# K32L2B21A register map
Vendor: NXP Semiconductors; Series: Kinetis; File version: 1.6
CPU: CM0PLUS r0p0, little endian, no MPU, no FPU, VTOR, 2 interrupt priority bits
Registers are 32-bit, read-write, reset 0x0 unless marked. A register's access mark holds for its fields unless they carry their own. Offsets are from the block's base; [hi:lo] are bit positions; {n}, {i} and the like mark numbered series; 'fields as' and 'values as' point back to an identical list.

## PORTB — Pin Control and Interrupts
Base 0x4004A000; register names take the prefix PORTB_
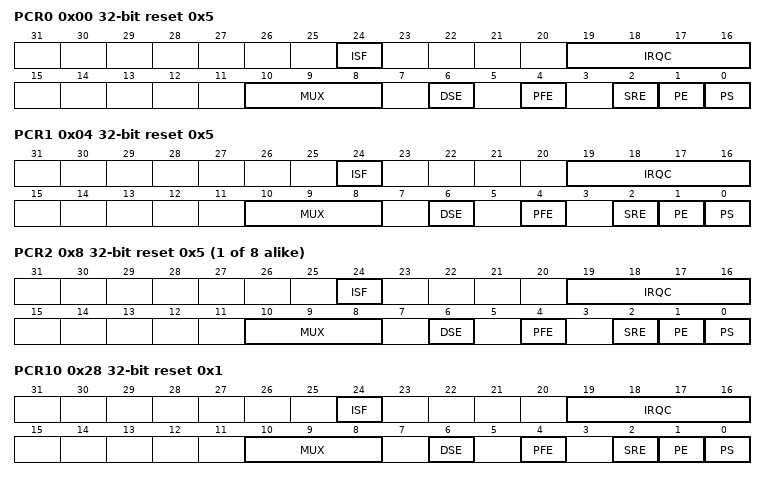
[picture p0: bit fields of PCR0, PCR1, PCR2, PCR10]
0x00 PCR0 reset 0x5 — Pin Control Register n
  [24] ISF — Interrupt Status Flag
    0=Configured interrupt is not detected; 1=Configured interrupt is detected. If the pin is configured to generate a DMA request, then the corresponding flag will be cleared automatically at the completion of the requested DMA transfer. Otherwise, the flag remains set until a logic 1 is written to the flag. If the pin is configured for a level sensitive interrupt and the pin remains asserted, then the flag is set again immediately after it is cleared.
  [19:16] IRQC — Interrupt Configuration
    0=Interrupt Status Flag (ISF) is disabled; 1=ISF flag and DMA request on rising edge; 2=ISF flag and DMA request on falling edge; 3=ISF flag and DMA request on either edge; 8=ISF flag and Interrupt when logic 0; 9=ISF flag and Interrupt on rising-edge; 10=ISF flag and Interrupt on falling-edge; 11=ISF flag and Interrupt on either edge; 12=ISF flag and Interrupt when logic 1
  [10:8] MUX — Pin Mux Control
    0=Pin disabled (Alternative 0) (analog); 1=Alternative 1 (GPIO); {v}=Alternative {v} (chip-specific) (v=2..7)
  [6] DSE — Drive Strength Enable
    0=Low drive strength is configured on the corresponding pin, if pin is configured as a digital output; 1=High drive strength is configured on the corresponding pin, if pin is configured as a digital output
  [4] PFE ro — Passive Filter Enable
    0=Passive input filter is disabled on the corresponding pin; 1=Passive input filter is enabled on the corresponding pin, if the pin is configured as a digital input. Refer to the device data sheet for filter characteristics.
  [2] SRE — Slew Rate Enable
    0=Fast slew rate is configured on the corresponding pin, if the pin is configured as a digital output; 1=Slow slew rate is configured on the corresponding pin, if the pin is configured as a digital output
  [1] PE — Pull Enable
    0=Internal pullup or pulldown resistor is not enabled on the corresponding pin; 1=Internal pullup or pulldown resistor is enabled on the corresponding pin, if the pin is configured as a digital input
  [0] PS — Pull Select
    0=Internal pulldown resistor is enabled on the corresponding pin, if the corresponding PE field is set; 1=Internal pullup resistor is enabled on the corresponding pin, if the corresponding PE field is set
0x04 PCR1 reset 0x5 — Pin Control Register n
  fields as PCR0
{0x0+4i} PCR{i} reset 0x5 (i=2..9) — Pin Control Register n
  [24] ISF — Interrupt Status Flag
    values as PCR0.ISF
  [19:16] IRQC — Interrupt Configuration
    values as PCR0.IRQC
  [10:8] MUX — Pin Mux Control
    values as PCR0.MUX
  [6] DSE ro — Drive Strength Enable
    values as PCR0.DSE
  [4] PFE ro — Passive Filter Enable
    values as PCR0.PFE
  [2] SRE ro — Slew Rate Enable
    values as PCR0.SRE
  [1] PE ro — Pull Enable
    values as PCR0.PE
  [0] PS ro — Pull Select
    values as PCR0.PS
0x28 PCR10 reset 0x1 — Pin Control Register n
  fields as PCR2
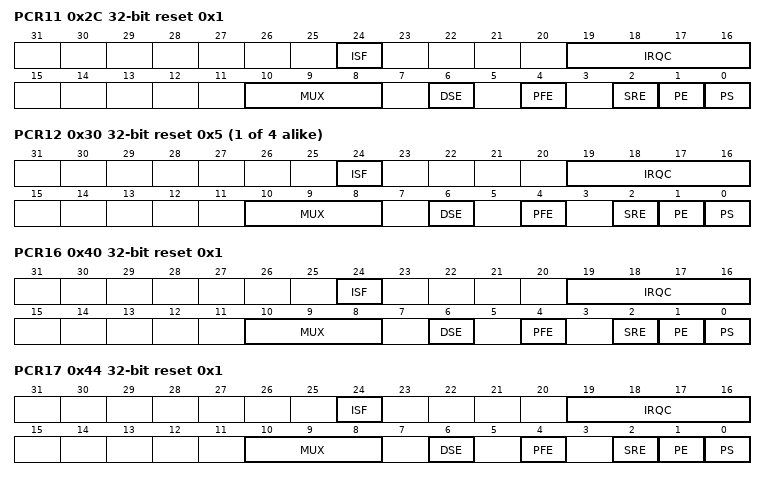
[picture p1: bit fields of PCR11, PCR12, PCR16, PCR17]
0x2C PCR11 reset 0x1 — Pin Control Register n
  fields as PCR2
{0x0+4i} PCR{i} reset 0x5 (i=12..15) — Pin Control Register n
  fields as PCR2
0x40 PCR16 reset 0x1 — Pin Control Register n
  fields as PCR2
0x44 PCR17 reset 0x1 — Pin Control Register n
  fields as PCR2
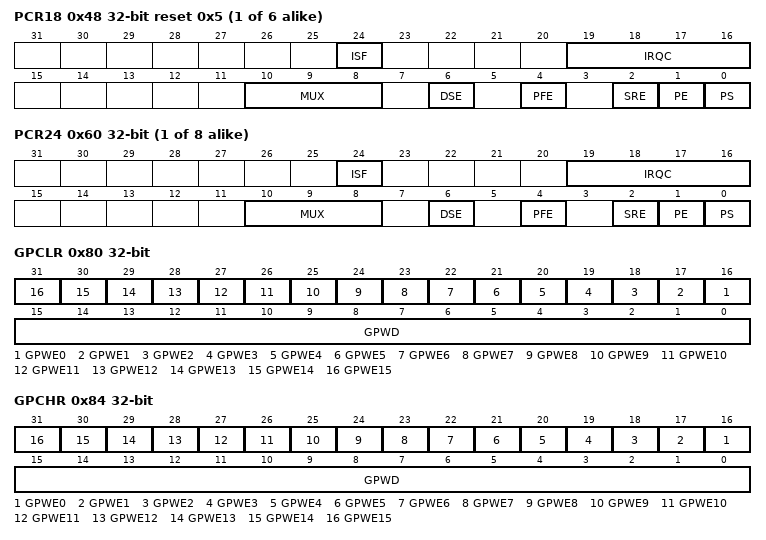
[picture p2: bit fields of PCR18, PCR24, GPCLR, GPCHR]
{0x0+4i} PCR{i} reset 0x5 (i=18..23) — Pin Control Register n
  fields as PCR2
{0x0+4i} PCR{i} (i=24..31) — Pin Control Register n
  fields as PCR2
0x80 GPCLR — Global Pin Control Low Register
  [n+16] GPWE{n} (n=0..15) — Global Pin Write Enable
    0=Corresponding Pin Control Register is not updated with the value in GPWD; 1=Corresponding Pin Control Register is updated with the value in GPWD
  [15:0] GPWD — Global Pin Write Data
0x84 GPCHR — Global Pin Control High Register
  fields as GPCLR
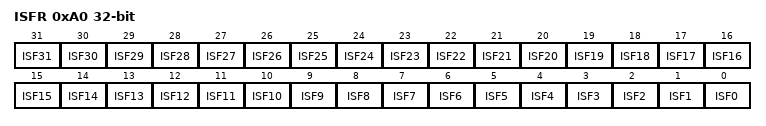
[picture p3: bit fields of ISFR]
0xA0 ISFR — Interrupt Status Flag Register
  [all] fields
    values as PCR0.ISF
  [n] ISF{n} (n=0..31) — Interrupt Status Flag

## PORTC — Pin Control and Interrupts
Base 0x4004B000; register names take the prefix PORTC_
Registers as PORTB; these are added or differ:
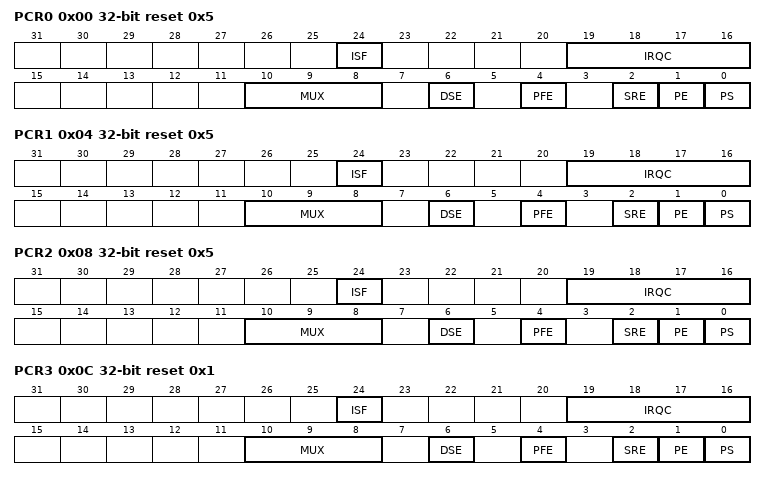
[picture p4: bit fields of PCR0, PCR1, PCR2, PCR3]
0x00 PCR0 reset 0x5 — Pin Control Register n
  fields as PORTB.PCR2
0x04 PCR1 reset 0x5 — Pin Control Register n
  [24] ISF — Interrupt Status Flag
    values as PORTB.PCR0.ISF
  [19:16] IRQC — Interrupt Configuration
    values as PORTB.PCR0.IRQC
  [10:8] MUX — Pin Mux Control
    0=Pin disabled (Alternative 0) (analog); 1=Alternative 1 (GPIO); {v}=Alternative {v} (chip-specific) (v=2..7)
  [6] DSE ro — Drive Strength Enable
    values as PORTB.PCR0.DSE
  [4] PFE ro — Passive Filter Enable
    values as PORTB.PCR0.PFE
  [2] SRE — Slew Rate Enable
    values as PORTB.PCR0.SRE
  [1] PE — Pull Enable
    0=Internal pullup or pulldown resistor is not enabled on the corresponding pin; 1=Internal pullup or pulldown resistor is enabled on the corresponding pin, if the pin is configured as a digital input
  [0] PS — Pull Select
    values as PORTB.PCR0.PS
0x08 PCR2 reset 0x5 — Pin Control Register n
  fields as PCR1
0x0C PCR3 reset 0x1 — Pin Control Register n
  fields as PORTB.PCR0
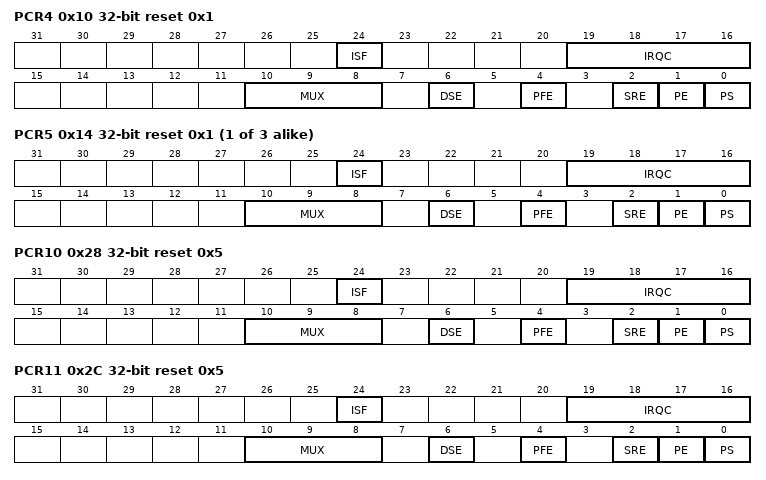
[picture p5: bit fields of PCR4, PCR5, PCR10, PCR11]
0x10 PCR4 reset 0x1 — Pin Control Register n
  fields as PORTB.PCR0
{0x0+4i} PCR{i} reset 0x1 (i=5..7) — Pin Control Register n
  fields as PCR1
0x28 PCR10 reset 0x5 — Pin Control Register n
  fields as PORTB.PCR2
0x2C PCR11 reset 0x5 — Pin Control Register n
  fields as PORTB.PCR2
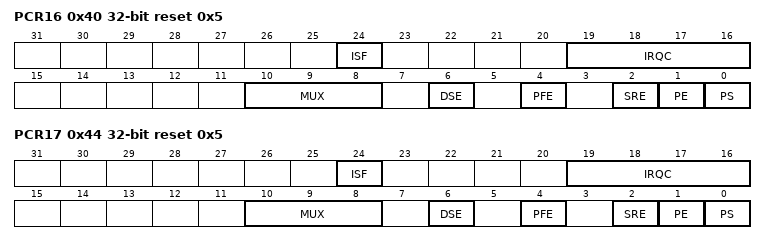
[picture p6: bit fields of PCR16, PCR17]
0x40 PCR16 reset 0x5 — Pin Control Register n
  fields as PORTB.PCR2
0x44 PCR17 reset 0x5 — Pin Control Register n
  fields as PORTB.PCR2

## PORTD — Pin Control and Interrupts
Base 0x4004C000; register names take the prefix PORTD_
Registers as PORTC; these are added or differ:
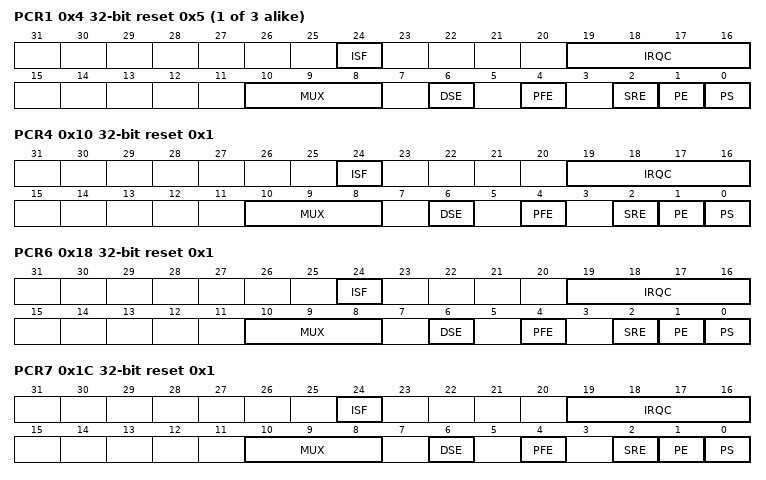
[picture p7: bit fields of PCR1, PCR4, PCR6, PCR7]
{0x0+4i} PCR{i} reset 0x5 (i=1..3) — Pin Control Register n
  fields as PORTB.PCR2
0x10 PCR4 reset 0x1 — Pin Control Register n
  fields as PORTC.PCR1
0x18 PCR6 reset 0x1 — Pin Control Register n
  fields as PORTB.PCR0
0x1C PCR7 reset 0x1 — Pin Control Register n
  fields as PORTB.PCR0
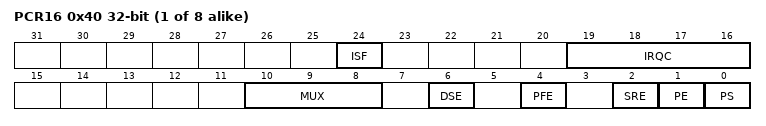
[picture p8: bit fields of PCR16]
{0x0+4i} PCR{i} (i=16..23) — Pin Control Register n
  fields as PORTB.PCR2
